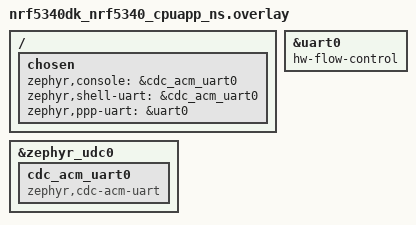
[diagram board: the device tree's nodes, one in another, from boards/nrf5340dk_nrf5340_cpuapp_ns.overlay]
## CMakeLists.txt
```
#
# Copyright (c) 2024 VoxelBotics
#

cmake_minimum_required(VERSION 3.20.0)

list(APPEND BOARD_ROOT ${CMAKE_CURRENT_SOURCE_DIR}/..)
find_package(Zephyr REQUIRED HINTS $ENV{ZEPHYR_BASE})
project(imd-nrf)

# NORDIC SDK APP START
target_sources(app PRIVATE
	src/main.c
	src/usb_uart.c
	src/bt_central_ht.c
)

add_subdirectory(src/addons)

# NORDIC SDK APP END

# Include source directory
target_include_directories(app PRIVATE src)
```

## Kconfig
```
#
# Copyright (c) 2021 Nordic Semiconductor ASA
#
# SPDX-License-Identifier: LicenseRef-Nordic-5-Clause
#

config UART_INTERRUPT_DRIVEN
	default y if SERIAL

rsource "src/addons/Kconfig"

menu "Zephyr Kernel"
source "Kconfig.zephyr"
endmenu

module = APPLICATION_MODULE
module-str = Application module
source "subsys/logging/Kconfig.template.log_config"
```

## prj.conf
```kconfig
#
# Copyright (c) 2024 VoxelBotics
#

# Enable NRF53 Network MCU
CONFIG_BOARD_ENABLE_CPUNET=y

# General
CONFIG_ASSERT=y

# Stacks and heaps
CONFIG_MAIN_STACK_SIZE=3072
CONFIG_SHELL_STACK_SIZE=2048
CONFIG_SYSTEM_WORKQUEUE_STACK_SIZE=2048
CONFIG_HEAP_MEM_POOL_SIZE=8192

# USB CDC ACM
CONFIG_USB_DEVICE_STACK_NEXT=y
CONFIG_USBD_CDC_ACM_CLASS=y

# Serial
CONFIG_SERIAL=y
CONFIG_UART_LINE_CTRL=y

# Logging
CONFIG_LOG=y
CONFIG_LOG_DEFAULT_LEVEL=3
CONFIG_USBD_LOG_LEVEL_WRN=y
CONFIG_USBD_CDC_ACM_LOG_LEVEL_WRN=y
CONFIG_UDC_DRIVER_LOG_LEVEL_WRN=y

# Shell related defines
CONFIG_SHELL=y
CONFIG_KERNEL_SHELL=y
CONFIG_SHELL_VT100_COLORS=y
CONFIG_SHELL_CMD_BUFF_SIZE=128
## Reduce shell memory usage
CONFIG_SHELL_WILDCARD=n
CONFIG_SHELL_HELP_ON_WRONG_ARGUMENT_COUNT=n
CONFIG_SHELL_STATS=n
CONFIG_SHELL_CMDS=n
CONFIG_SHELL_HISTORY=y

# For testing flash
CONFIG_FLASH=y
CONFIG_FLASH_SHELL=y
CONFIG_FLASH_SHELL_TEST_COMMANDS=y

# Networking
CONFIG_NET_PPP=y
CONFIG_NET_PPP_LOG_LEVEL_INF=y
CONFIG_NETWORKING=y
CONFIG_NET_NATIVE=y
CONFIG_NET_DRIVERS=y
CONFIG_NET_L2_PPP=y
CONFIG_NET_LOG=y
CONFIG_NET_L2_PPP_LOG_LEVEL_INF=y

CONFIG_NET_SHELL=y
CONFIG_NET_TCP=y
CONFIG_NET_IPV4=y

CONFIG_NET_CONFIG_SETTINGS=y
CONFIG_NET_CONFIG_NEED_IPV4=y
CONFIG_NET_CONFIG_MY_IPV4_ADDR="192.0.2.2"

# Bluetooth
CONFIG_BT=y
CONFIG_BT_CENTRAL=y
CONFIG_BT_SMP=y
CONFIG_BT_GATT_CLIENT=y

# Floating point formatting in cbprintf (needed for BT HT demo)
CONFIG_CBPRINTF_FP_SUPPORT=y
```

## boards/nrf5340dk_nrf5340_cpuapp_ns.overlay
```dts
/*
 * Copyright (c) 2024 VoxelBotics
 */

/ {
	chosen {
		zephyr,console = &cdc_acm_uart0;
		zephyr,shell-uart = &cdc_acm_uart0;
		zephyr,ppp-uart = &uart0;
	};
};

&zephyr_udc0 {
	cdc_acm_uart0: cdc_acm_uart0 {
		compatible = "zephyr,cdc-acm-uart";
	};
};

&uart0 {
	status = "okay";
	hw-flow-control;
};
```

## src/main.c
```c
/*
 * Copyright (c) 2024 VoxelBotics
 */

#include <zephyr/kernel.h>
#include <zephyr/logging/log.h>
#include "config.h"
#include "usb_uart.h"

LOG_MODULE_REGISTER(app);

int main(void)
{
	if (usb_uart_enable()) {
		return 0;
	}

	LOG_INF("Start thingy9151lite_nrf5340_cpuapp_app v%d.%d-%d-%s on %s",
		CONFIG_VERSION_MAJOR,
		CONFIG_VERSION_MINOR,
		CONFIG_BUILD_NUMBER,
		CONFIG_BUILD_DEBUG ? "debug" : "release",
		CONFIG_BOARD);

	return 0;
}
```

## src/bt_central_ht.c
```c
/*
 * Copyright (c) 2020 SixOctets Systems
 * Copyright (c) 2024 Emcraft Systems
 *
 * SPDX-License-Identifier: Apache-2.0
 */

#include <stdio.h>
#include <stddef.h>
#include <errno.h>

#include <zephyr/kernel.h>
#include <zephyr/sys/printk.h>
#include <zephyr/sys/byteorder.h>
#include <zephyr/shell/shell.h>

#include <zephyr/bluetooth/bluetooth.h>
#include <zephyr/bluetooth/hci.h>
#include <zephyr/bluetooth/conn.h>
#include <zephyr/bluetooth/uuid.h>
#include <zephyr/bluetooth/gatt.h>

#include <zephyr/logging/log.h>
LOG_MODULE_REGISTER(bt_central_ht);

static int scan_start(void);

static struct bt_conn *default_conn;
static struct bt_uuid_16 discover_uuid = BT_UUID_INIT_16(0);
static struct bt_gatt_discover_params discover_params;
static struct bt_gatt_subscribe_params subscribe_params;

static double pow(double x, double y)
{
	double result = 1;

	if (y < 0) {
		y = -y;
		while (y--) {
			result /= x;
		}
	} else {
		while (y--) {
			result *= x;
		}
	}

	return result;
}

static uint8_t notify_func(struct bt_conn *conn,
			   struct bt_gatt_subscribe_params *params,
			   const void *data, uint16_t length)
{
	static uint32_t print_count = 0;
	double temperature;
	uint32_t mantissa;
	int8_t exponent;

	if (!data) {
		LOG_INF("[UNSUBSCRIBED]");
		params->value_handle = 0U;
		return BT_GATT_ITER_STOP;
	}

	/* temperature value display */
	mantissa = sys_get_le24(&((uint8_t *)data)[1]);
	exponent = ((uint8_t *)data)[4];
	temperature = (double)mantissa * pow(10, exponent);

	print_count++;
	if (print_count <= 10 || print_count % 60 == 0) {
		LOG_INF("Temperature %gC.", temperature);
	} else {
		LOG_DBG("Temperature %gC.", temperature);
	}

	return BT_GATT_ITER_CONTINUE;
}

static uint8_t discover_func(struct bt_conn *conn,
			     const struct bt_gatt_attr *attr,
			     struct bt_gatt_discover_params *params)
{
	int err;

	if (!attr) {
		LOG_INF("Discover complete");
		(void)memset(params, 0, sizeof(*params));
		return BT_GATT_ITER_STOP;
	}

	LOG_INF("[ATTRIBUTE] handle %u", attr->handle);

	if (!bt_uuid_cmp(discover_params.uuid, BT_UUID_HTS)) {
		memcpy(&discover_uuid, BT_UUID_HTS_MEASUREMENT, sizeof(discover_uuid));
		discover_params.uuid = &discover_uuid.uuid;
		discover_params.start_handle = attr->handle + 1;
		discover_params.type = BT_GATT_DISCOVER_CHARACTERISTIC;

		err = bt_gatt_discover(conn, &discover_params);
		if (err) {
			LOG_ERR("Discover failed (err %d)", err);
		}
	} else if (!bt_uuid_cmp(discover_params.uuid,
				BT_UUID_HTS_MEASUREMENT)) {
		memcpy(&discover_uuid, BT_UUID_GATT_CCC, sizeof(discover_uuid));
		discover_params.uuid = &discover_uuid.uuid;
		discover_params.start_handle = attr->handle + 2;
		discover_params.type = BT_GATT_DISCOVER_DESCRIPTOR;
		subscribe_params.value_handle = bt_gatt_attr_value_handle(attr);

		err = bt_gatt_discover(conn, &discover_params);
		if (err) {
			LOG_ERR("Discover failed (err %d)", err);
		}
	} else {
		subscribe_params.notify = notify_func;
		subscribe_params.value = BT_GATT_CCC_INDICATE;
		subscribe_params.ccc_handle = attr->handle;

		err = bt_gatt_subscribe(conn, &subscribe_params);
		if (err && err != -EALREADY) {
			LOG_ERR("Subscribe failed (err %d)", err);
		} else {
			LOG_INF("[SUBSCRIBED]");
		}

		return BT_GATT_ITER_STOP;
	}

	return BT_GATT_ITER_STOP;
}

static void connected(struct bt_conn *conn, uint8_t conn_err)
{
	char addr[BT_ADDR_LE_STR_LEN];
	int err;

	bt_addr_le_to_str(bt_conn_get_dst(conn), addr, sizeof(addr));

	if (conn_err) {
		LOG_ERR("Failed to connect to %s (%u)", addr, conn_err);

		bt_conn_unref(default_conn);
		default_conn = NULL;

		scan_start();
		return;
	}

	LOG_INF("Connected: %s", addr);

	if (conn == default_conn) {
		memcpy(&discover_uuid, BT_UUID_HTS, sizeof(discover_uuid));
		discover_params.uuid = &discover_uuid.uuid;
		discover_params.func = discover_func;
		discover_params.start_handle = BT_ATT_FIRST_ATTRIBUTE_HANDLE;
		discover_params.end_handle = BT_ATT_LAST_ATTRIBUTE_HANDLE;
		discover_params.type = BT_GATT_DISCOVER_PRIMARY;

		err = bt_gatt_discover(default_conn, &discover_params);
		if (err) {
			LOG_ERR("Discover failed(err %d)", err);
			return;
		}
	}
}

static bool eir_found(struct bt_data *data, void *user_data)
{
	bt_addr_le_t *addr = user_data;
	int i;

	LOG_DBG("[AD]: %u data_len %u", data->type, data->data_len);

	switch (data->type) {
	case BT_DATA_UUID16_SOME:
	case BT_DATA_UUID16_ALL:
		if (data->data_len % sizeof(uint16_t) != 0U) {
			LOG_ERR("AD malformed");
			return true;
		}

		for (i = 0; i < data->data_len; i += sizeof(uint16_t)) {
			struct bt_uuid *uuid;
			uint16_t u16;
			int err;

			memcpy(&u16, &data->data[i], sizeof(u16));
			uuid = BT_UUID_DECLARE_16(sys_le16_to_cpu(u16));
			if (bt_uuid_cmp(uuid, BT_UUID_HTS)) {
				continue;
			}

			err = bt_le_scan_stop();
			if (err) {
				LOG_ERR("Stop LE scan failed (err %d)", err);
				continue;
			}

			err = bt_conn_le_create(addr, BT_CONN_LE_CREATE_CONN,
						BT_LE_CONN_PARAM_DEFAULT,
						&default_conn);
			if (err) {
				LOG_ERR("Create connection failed (err %d)",
				       err);
				scan_start();
			}

			return false;
		}
	}

	return true;
}

static void device_found(const bt_addr_le_t *addr, int8_t rssi, uint8_t type,
			 struct net_buf_simple *ad)
{
	char dev[BT_ADDR_LE_STR_LEN];

	bt_addr_le_to_str(addr, dev, sizeof(dev));
	LOG_DBG("[DEVICE]: %s, AD evt type %u, AD data len %u, RSSI %i",
	       dev, type, ad->len, rssi);

	/* We're only interested in connectable events */
	if (type == BT_HCI_ADV_IND || type == BT_HCI_ADV_DIRECT_IND) {
		bt_data_parse(ad, eir_found, (void *)addr);
	}
}

static int scan_start(void)
{
	/* Use active scanning and disable duplicate filtering to handle any
	 * devices that might update their advertising data at runtime.
	 */
	struct bt_le_scan_param scan_param = {
		.type       = BT_LE_SCAN_TYPE_ACTIVE,
		.options    = BT_LE_SCAN_OPT_NONE,
		.interval   = BT_GAP_SCAN_FAST_INTERVAL,
		.window     = BT_GAP_SCAN_FAST_WINDOW,
	};

	return bt_le_scan_start(&scan_param, device_found);
}

static void disconnected(struct bt_conn *conn, uint8_t reason)
{
	char addr[BT_ADDR_LE_STR_LEN];
	int err;

	bt_addr_le_to_str(bt_conn_get_dst(conn), addr, sizeof(addr));

	LOG_INF("Disconnected: %s (reason 0x%02x)", addr, reason);

	if (default_conn != conn) {
		return;
	}

	bt_conn_unref(default_conn);
	default_conn = NULL;

	err = scan_start();
	if (err) {
		LOG_ERR("Scanning failed to start (err %d)", err);
	}
}

BT_CONN_CB_DEFINE(conn_callbacks) = {
	.connected = connected,
	.disconnected = disconnected,
};

static int cmd_bt_central_ht_start(const struct shell *sh, size_t argc, char **argv)
{
	int err;

	err = bt_enable(NULL);
	if (err) {
		shell_error(sh, "Bluetooth init failed (err %d)", err);
		return 0;
	}

	shell_print(sh, "Bluetooth initialized");

	err = scan_start();

	if (err) {
		shell_error(sh, "Scanning failed to start (err %d)", err);
		return 0;
	}

	shell_print(sh, "Scanning successfully started");
	return 0;
}

#if IS_ENABLED(CONFIG_SHELL)
SHELL_STATIC_SUBCMD_SET_CREATE(sub_bt_central_ht,
	SHELL_CMD(start, NULL, "Start Health Thermometer sensor sample", cmd_bt_central_ht_start),
	SHELL_SUBCMD_SET_END
);

SHELL_CMD_REGISTER(bt_central_ht, &sub_bt_central_ht, "Bluetooth Central Health Thermometer sensor sample", NULL);
#endif /* CONFIG_SHELL */
```

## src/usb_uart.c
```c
/*
 * Copyright (c) 2024 VoxelBotics
 */

#include <zephyr/kernel.h>
#include <zephyr/usb/usb_device.h>
#include <zephyr/usb/usbd.h>
#include <zephyr/drivers/uart.h>
#include "config.h"
#include "usb_uart.h"

USBD_CONFIGURATION_DEFINE(config_1,
			  USB_SCD_SELF_POWERED,
			  200);

USBD_DESC_LANG_DEFINE(lang);
USBD_DESC_MANUFACTURER_DEFINE(mfr, "ZEPHYR");
USBD_DESC_PRODUCT_DEFINE(product, "Zephyr USBD ACM console");
USBD_DESC_SERIAL_NUMBER_DEFINE(sn, "0123456789ABCDEF");

USBD_DEVICE_DEFINE(usbd,
		   DEVICE_DT_GET(DT_NODELABEL(zephyr_udc0)),
		   0x2fe3, 0x0001);

int usb_uart_enable(void)
{
	int err;

	err = usbd_add_descriptor(&usbd, &lang);
	if (err) {
		return err;
	}

	err = usbd_add_descriptor(&usbd, &mfr);
	if (err) {
		return err;
	}

	err = usbd_add_descriptor(&usbd, &product);
	if (err) {
		return err;
	}

	err = usbd_add_descriptor(&usbd, &sn);
	if (err) {
		return err;
	}

	err = usbd_add_configuration(&usbd, &config_1);
	if (err) {
		return err;
	}

	err = usbd_register_class(&usbd, "cdc_acm_0", 1);
	if (err) {
		return err;
	}

	err = usbd_init(&usbd);
	if (err) {
		return err;
	}

	err = usbd_enable(&usbd);
	if (err) {
		return err;
	}

	return 0;
}
```

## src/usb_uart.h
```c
/*
 * Copyright (c) 2024 VoxelBotics
 */

#ifndef USB_UART_H_
#define USB_UART_H_

/**
 * @brief Enable the USB UART (CDC-ACM) device
 *
 * @return 0 on success, other values on fail.
 */
int usb_uart_enable(void);

#endif
```
